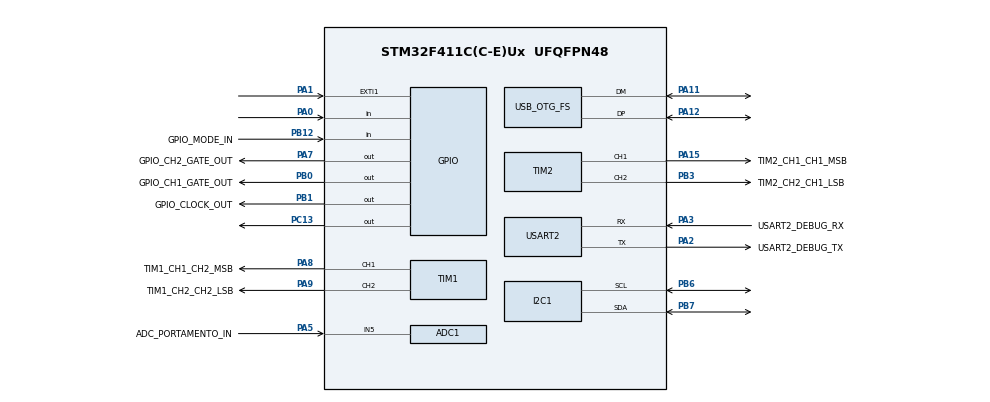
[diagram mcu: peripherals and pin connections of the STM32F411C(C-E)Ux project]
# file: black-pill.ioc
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ADC1.Channel-3\#ChannelRegularConversion=ADC_CHANNEL_5
ADC1.NbrOfConversionFlag=1
ADC1.Rank-3\#ChannelRegularConversion=1
ADC1.SamplingTime-3\#ChannelRegularConversion=ADC_SAMPLETIME_3CYCLES
ADC1.master=1
Mcu.Family=STM32F4
Mcu.Name=STM32F411C(C-E)Ux
Mcu.Package=UFQFPN48
NVIC.PriorityGroup=NVIC_PRIORITYGROUP_4
PA0-WKUP.Signal=GPIO_Input
PA1.Signal=GPXTI1
PA10.GPIO_Label=USART1_MIDI_RX
PA10.GPIO_PuPd=GPIO_PULLUP
PA10.Signal=USART1_RX
PA11.Mode=Device_Only
PA11.Signal=USB_OTG_FS_DM
PA12.Mode=Device_Only
PA12.Signal=USB_OTG_FS_DP
PA13.Mode=Serial_Wire
PA13.Signal=SYS_JTMS-SWDIO
PA14.Mode=Serial_Wire
PA14.Signal=SYS_JTCK-SWCLK
PA15.GPIO_Label=TIM2_CH1_CH1_MSB
PA15.Signal=S_TIM2_CH1_ETR
PA2.GPIO_Label=USART2_DEBUG_TX
PA2.GPIO_PuPd=GPIO_PULLUP
PA2.Mode=Asynchronous
PA2.Signal=USART2_TX
PA3.GPIO_Label=USART2_DEBUG_RX
PA3.GPIO_PuPd=GPIO_PULLUP
PA3.Mode=Asynchronous
PA3.Signal=USART2_RX
PA5.GPIO_Label=ADC_PORTAMENTO_IN
PA5.Signal=ADCx_IN5
PA7.GPIO_Label=GPIO_CH2_GATE_OUT
PA7.Signal=GPIO_Output
PA8.GPIO_Label=TIM1_CH1_CH2_MSB
PA8.GPIO_Speed=GPIO_SPEED_FREQ_VERY_HIGH
PA8.Signal=S_TIM1_CH1
PA9.GPIO_Label=TIM1_CH2_CH2_LSB
PA9.GPIO_Speed=GPIO_SPEED_FREQ_VERY_HIGH
PA9.Signal=S_TIM1_CH2
PB0.GPIO_Label=GPIO_CH1_GATE_OUT
PB0.Signal=GPIO_Output
PB1.GPIO_Label=GPIO_CLOCK_OUT
PB1.Signal=GPIO_Output
PB12.GPIO_Label=GPIO_MODE_IN
PB12.Signal=GPIO_Input
PB3.GPIO_Label=TIM2_CH2_CH1_LSB
PB3.Signal=S_TIM2_CH2
PB6.Mode=I2C
PB6.Signal=I2C1_SCL
PB7.Mode=I2C
PB7.Signal=I2C1_SDA
PC13-ANTI_TAMP.Signal=GPIO_Output
PH0\ -\ OSC_IN.Mode=HSE-External-Oscillator
PH0\ -\ OSC_IN.Signal=RCC_OSC_IN
PH1\ -\ OSC_OUT.Mode=HSE-External-Oscillator
PH1\ -\ OSC_OUT.Signal=RCC_OSC_OUT
ProjectManager.HeapSize=0x200
ProjectManager.StackSize=0x400
ProjectManager.TargetToolchain=Makefile
RCC.48MHZClocksFreq_Value=48000000
RCC.AHBFreq_Value=96000000
RCC.APB1CLKDivider=RCC_HCLK_DIV2
RCC.APB1Freq_Value=48000000
RCC.APB1TimFreq_Value=96000000
RCC.APB2Freq_Value=96000000
RCC.APB2TimFreq_Value=96000000
RCC.CortexFreq_Value=96000000
RCC.HCLKFreq_Value=96000000
RCC.HSE_VALUE=25000000
RCC.HSI_VALUE=16000000
RCC.LSE_VALUE=32768
RCC.PLLM=25
RCC.SYSCLKFreq_VALUE=96000000
RCC.SYSCLKSource=RCC_SYSCLKSOURCE_PLLCLK
RCC.VCOOutputFreq_Value=192000000
SH.ADCx_IN5.0=ADC1_IN5,IN5
SH.S_TIM1_CH1.0=TIM1_CH1,PWM Generation1 CH1
SH.S_TIM1_CH2.0=TIM1_CH2,PWM Generation2 CH2
SH.S_TIM2_CH1_ETR.0=TIM2_CH1,PWM Generation1 CH1
SH.S_TIM2_CH2.0=TIM2_CH2,Output Compare2 CH2
TIM1.AutoReloadPreload=TIM_AUTORELOAD_PRELOAD_ENABLE
TIM1.Channel-PWM\ Generation1\ CH1=TIM_CHANNEL_1
TIM1.Channel-PWM\ Generation2\ CH2=TIM_CHANNEL_2
TIM2.AutoReloadPreload=TIM_AUTORELOAD_PRELOAD_ENABLE
TIM2.Channel-Output\ Compare2\ CH2=TIM_CHANNEL_2
TIM2.Channel-PWM\ Generation1\ CH1=TIM_CHANNEL_1
USART2.VirtualMode=VM_ASYNC
USB_OTG_FS.VirtualMode=Device_Only
VP_TIM1_VS_ClockSourceINT.Mode=Internal
VP_TIM2_VS_ClockSourceINT.Mode=Internal
board=custom

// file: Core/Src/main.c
/* USER CODE BEGIN Header */
/**
  ******************************************************************************
  * @file           : main.c
  * @brief          : Main program body
  ******************************************************************************
  * @attention
  *
  * <h2><center>&copy; Copyright (c) 2021 STMicroelectronics.
  * All rights reserved.</center></h2>
  *
  * This software component is licensed by ST under BSD 3-Clause license,
  * the "License"; You may not use this file except in compliance with the
  * License. You may obtain a copy of the License at:
  *                        opensource.org/licenses/BSD-3-Clause
  *
  ******************************************************************************
  */
/* USER CODE END Header */
#include "main.h"

/* USER CODE BEGIN Includes */
#include "app.h"
#include "usb_device.h"
/* USER CODE END Includes */

void SystemClock_Config(void);
static void MX_GPIO_Init(void);
static void MX_USART2_UART_Init(void);
static void MX_ADC1_Init(void);
static void MX_TIM1_Init(void);
static void MX_TIM2_Init(void);
static void MX_I2C1_Init(void);

int main(void)
{
  /* USER CODE BEGIN 1 */

    /*HAL_Init();
  SystemClock_Config();
  LL_AHB1_GRP1_EnableClock(LL_AHB1_GRP1_PERIPH_GPIOA);
  LL_AHB1_GRP1_EnableClock(LL_AHB1_GRP1_PERIPH_GPIOB);
  LL_AHB1_GRP1_EnableClock(LL_AHB1_GRP1_PERIPH_GPIOC);
  LL_AHB1_GRP1_EnableClock(LL_AHB1_GRP1_PERIPH_GPIOH);
  LL_APB2_GRP1_EnableClock(LL_APB2_GRP1_PERIPH_USART1);
  LL_APB1_GRP1_EnableClock(LL_APB1_GRP1_PERIPH_USART2);
  app_main();
  return 0;*/

  /* USER CODE END 1 */

  /* MCU Configuration--------------------------------------------------------*/

  /* Reset of all peripherals, Initializes the Flash interface and the Systick. */
  HAL_Init();

  /* Configure the system clock */
  SystemClock_Config();

  /* Initialize all configured peripherals */
  MX_GPIO_Init();
  MX_USART2_UART_Init();
  MX_ADC1_Init();
  MX_TIM1_Init();
  MX_TIM2_Init();
  MX_I2C1_Init();
  /* USER CODE BEGIN 2 */
    MX_USB_DEVICE_Init();
    app_main();
  /* USER CODE END 2 */

  /* Infinite loop */
    while(1) {

    }
}

void SystemClock_Config(void)
{
  LL_FLASH_SetLatency(LL_FLASH_LATENCY_3);
  while(LL_FLASH_GetLatency()!= LL_FLASH_LATENCY_3)
  {
  }
  LL_PWR_SetRegulVoltageScaling(LL_PWR_REGU_VOLTAGE_SCALE1);
  LL_RCC_HSE_Enable();

   /* Wait till HSE is ready */
  while(LL_RCC_HSE_IsReady() != 1)
  {

  }
  LL_RCC_PLL_ConfigDomain_SYS(LL_RCC_PLLSOURCE_HSE, LL_RCC_PLLM_DIV_25, 192, LL_RCC_PLLP_DIV_2);
  LL_RCC_PLL_ConfigDomain_48M(LL_RCC_PLLSOURCE_HSE, LL_RCC_PLLM_DIV_25, 192, LL_RCC_PLLQ_DIV_4);
  LL_RCC_PLL_Enable();

   /* Wait till PLL is ready */
  while(LL_RCC_PLL_IsReady() != 1)
  {

  }
  while (LL_PWR_IsActiveFlag_VOS() == 0)
  {
  }
  LL_RCC_SetAHBPrescaler(LL_RCC_SYSCLK_DIV_1);
  LL_RCC_SetAPB1Prescaler(LL_RCC_APB1_DIV_2);
  LL_RCC_SetAPB2Prescaler(LL_RCC_APB2_DIV_1);
  LL_RCC_SetSysClkSource(LL_RCC_SYS_CLKSOURCE_PLL);

   /* Wait till System clock is ready */
  while(LL_RCC_GetSysClkSource() != LL_RCC_SYS_CLKSOURCE_STATUS_PLL)
  {

  }
  LL_SetSystemCoreClock(96000000);

   /* Update the time base */
  if (HAL_InitTick (TICK_INT_PRIORITY) != HAL_OK)
  {
    Error_Handler();
  }
  LL_RCC_SetTIMPrescaler(LL_RCC_TIM_PRESCALER_TWICE);
}

static void MX_ADC1_Init(void)
{

  LL_ADC_InitTypeDef ADC_InitStruct = {0};
  LL_ADC_REG_InitTypeDef ADC_REG_InitStruct = {0};
  LL_ADC_CommonInitTypeDef ADC_CommonInitStruct = {0};

  LL_GPIO_InitTypeDef GPIO_InitStruct = {0};

  /* Peripheral clock enable */
  LL_APB2_GRP1_EnableClock(LL_APB2_GRP1_PERIPH_ADC1);

  LL_AHB1_GRP1_EnableClock(LL_AHB1_GRP1_PERIPH_GPIOA);
  /**ADC1 GPIO Configuration
  PA5   ------> ADC1_IN5
  */
  GPIO_InitStruct.Pin = ADC_PORTAMENTO_IN_Pin;
  GPIO_InitStruct.Mode = LL_GPIO_MODE_ANALOG;
  GPIO_InitStruct.Pull = LL_GPIO_PULL_NO;
  LL_GPIO_Init(ADC_PORTAMENTO_IN_GPIO_Port, &GPIO_InitStruct);

  /** Common config
  */
  ADC_InitStruct.Resolution = LL_ADC_RESOLUTION_12B;
  ADC_InitStruct.DataAlignment = LL_ADC_DATA_ALIGN_RIGHT;
  ADC_InitStruct.SequencersScanMode = LL_ADC_SEQ_SCAN_DISABLE;
  LL_ADC_Init(ADC1, &ADC_InitStruct);
  ADC_REG_InitStruct.TriggerSource = LL_ADC_REG_TRIG_SOFTWARE;
  ADC_REG_InitStruct.SequencerLength = LL_ADC_REG_SEQ_SCAN_DISABLE;
  ADC_REG_InitStruct.SequencerDiscont = LL_ADC_REG_SEQ_DISCONT_DISABLE;
  ADC_REG_InitStruct.ContinuousMode = LL_ADC_REG_CONV_SINGLE;
  ADC_REG_InitStruct.DMATransfer = LL_ADC_REG_DMA_TRANSFER_NONE;
  LL_ADC_REG_Init(ADC1, &ADC_REG_InitStruct);
  LL_ADC_REG_SetFlagEndOfConversion(ADC1, LL_ADC_REG_FLAG_EOC_UNITARY_CONV);
  ADC_CommonInitStruct.CommonClock = LL_ADC_CLOCK_SYNC_PCLK_DIV4;
  LL_ADC_CommonInit(__LL_ADC_COMMON_INSTANCE(ADC1), &ADC_CommonInitStruct);

  /** Configure Regular Channel
  */
  LL_ADC_REG_SetSequencerRanks(ADC1, LL_ADC_REG_RANK_1, LL_ADC_CHANNEL_5);
  LL_ADC_SetChannelSamplingTime(ADC1, LL_ADC_CHANNEL_5, LL_ADC_SAMPLINGTIME_3CYCLES);

}

static void MX_I2C1_Init(void)
{

  LL_I2C_InitTypeDef I2C_InitStruct = {0};

  LL_GPIO_InitTypeDef GPIO_InitStruct = {0};

  LL_AHB1_GRP1_EnableClock(LL_AHB1_GRP1_PERIPH_GPIOB);
  /**I2C1 GPIO Configuration
  PB6   ------> I2C1_SCL
  PB7   ------> I2C1_SDA
  */
  GPIO_InitStruct.Pin = LL_GPIO_PIN_6|LL_GPIO_PIN_7;
  GPIO_InitStruct.Mode = LL_GPIO_MODE_ALTERNATE;
  GPIO_InitStruct.Speed = LL_GPIO_SPEED_FREQ_VERY_HIGH;
  GPIO_InitStruct.OutputType = LL_GPIO_OUTPUT_OPENDRAIN;
  GPIO_InitStruct.Pull = LL_GPIO_PULL_NO;
  GPIO_InitStruct.Alternate = LL_GPIO_AF_4;
  LL_GPIO_Init(GPIOB, &GPIO_InitStruct);

  /* Peripheral clock enable */
  LL_APB1_GRP1_EnableClock(LL_APB1_GRP1_PERIPH_I2C1);

  /** I2C Initialization
  */
  LL_I2C_DisableOwnAddress2(I2C1);
  LL_I2C_DisableGeneralCall(I2C1);
  LL_I2C_EnableClockStretching(I2C1);
  I2C_InitStruct.PeripheralMode = LL_I2C_MODE_I2C;
  I2C_InitStruct.ClockSpeed = 100000;
  I2C_InitStruct.DutyCycle = LL_I2C_DUTYCYCLE_2;
  I2C_InitStruct.OwnAddress1 = 0;
  I2C_InitStruct.TypeAcknowledge = LL_I2C_ACK;
  I2C_InitStruct.OwnAddrSize = LL_I2C_OWNADDRESS1_7BIT;
  LL_I2C_Init(I2C1, &I2C_InitStruct);
  LL_I2C_SetOwnAddress2(I2C1, 0);

}

static void MX_TIM1_Init(void)
{

  LL_TIM_InitTypeDef TIM_InitStruct = {0};
  LL_TIM_OC_InitTypeDef TIM_OC_InitStruct = {0};
  LL_TIM_BDTR_InitTypeDef TIM_BDTRInitStruct = {0};

  LL_GPIO_InitTypeDef GPIO_InitStruct = {0};

  /* Peripheral clock enable */
  LL_APB2_GRP1_EnableClock(LL_APB2_GRP1_PERIPH_TIM1);

  TIM_InitStruct.Prescaler = 0;
  TIM_InitStruct.CounterMode = LL_TIM_COUNTERMODE_UP;
  TIM_InitStruct.Autoreload = 65535;
  TIM_InitStruct.ClockDivision = LL_TIM_CLOCKDIVISION_DIV1;
  TIM_InitStruct.RepetitionCounter = 0;
  LL_TIM_Init(TIM1, &TIM_InitStruct);
  LL_TIM_EnableARRPreload(TIM1);
  LL_TIM_SetClockSource(TIM1, LL_TIM_CLOCKSOURCE_INTERNAL);
  LL_TIM_OC_EnablePreload(TIM1, LL_TIM_CHANNEL_CH1);
  TIM_OC_InitStruct.OCMode = LL_TIM_OCMODE_PWM1;
  TIM_OC_InitStruct.OCState = LL_TIM_OCSTATE_DISABLE;
  TIM_OC_InitStruct.OCNState = LL_TIM_OCSTATE_DISABLE;
  TIM_OC_InitStruct.CompareValue = 0;
  TIM_OC_InitStruct.OCPolarity = LL_TIM_OCPOLARITY_HIGH;
  TIM_OC_InitStruct.OCNPolarity = LL_TIM_OCPOLARITY_HIGH;
  TIM_OC_InitStruct.OCIdleState = LL_TIM_OCIDLESTATE_LOW;
  TIM_OC_InitStruct.OCNIdleState = LL_TIM_OCIDLESTATE_LOW;
  LL_TIM_OC_Init(TIM1, LL_TIM_CHANNEL_CH1, &TIM_OC_InitStruct);
  LL_TIM_OC_DisableFast(TIM1, LL_TIM_CHANNEL_CH1);
  LL_TIM_OC_EnablePreload(TIM1, LL_TIM_CHANNEL_CH2);
  LL_TIM_OC_Init(TIM1, LL_TIM_CHANNEL_CH2, &TIM_OC_InitStruct);
  LL_TIM_OC_DisableFast(TIM1, LL_TIM_CHANNEL_CH2);
  LL_TIM_SetTriggerOutput(TIM1, LL_TIM_TRGO_RESET);
  LL_TIM_DisableMasterSlaveMode(TIM1);
  TIM_BDTRInitStruct.OSSRState = LL_TIM_OSSR_DISABLE;
  TIM_BDTRInitStruct.OSSIState = LL_TIM_OSSI_DISABLE;
  TIM_BDTRInitStruct.LockLevel = LL_TIM_LOCKLEVEL_OFF;
  TIM_BDTRInitStruct.DeadTime = 0;
  TIM_BDTRInitStruct.BreakState = LL_TIM_BREAK_DISABLE;
  TIM_BDTRInitStruct.BreakPolarity = LL_TIM_BREAK_POLARITY_HIGH;
  TIM_BDTRInitStruct.AutomaticOutput = LL_TIM_AUTOMATICOUTPUT_DISABLE;
  LL_TIM_BDTR_Init(TIM1, &TIM_BDTRInitStruct);
  LL_AHB1_GRP1_EnableClock(LL_AHB1_GRP1_PERIPH_GPIOA);
  /**TIM1 GPIO Configuration
  PA8   ------> TIM1_CH1
  PA9   ------> TIM1_CH2
  */
  GPIO_InitStruct.Pin = TIM1_CH1_CH2_MSB_Pin|TIM1_CH2_CH2_LSB_Pin;
  GPIO_InitStruct.Mode = LL_GPIO_MODE_ALTERNATE;
  GPIO_InitStruct.Speed = LL_GPIO_SPEED_FREQ_VERY_HIGH;
  GPIO_InitStruct.OutputType = LL_GPIO_OUTPUT_PUSHPULL;
  GPIO_InitStruct.Pull = LL_GPIO_PULL_NO;
  GPIO_InitStruct.Alternate = LL_GPIO_AF_1;
  LL_GPIO_Init(GPIOA, &GPIO_InitStruct);

}

static void MX_TIM2_Init(void)
{

  LL_TIM_InitTypeDef TIM_InitStruct = {0};
  LL_TIM_OC_InitTypeDef TIM_OC_InitStruct = {0};

  LL_GPIO_InitTypeDef GPIO_InitStruct = {0};

  /* Peripheral clock enable */
  LL_APB1_GRP1_EnableClock(LL_APB1_GRP1_PERIPH_TIM2);

  TIM_InitStruct.Prescaler = 0;
  TIM_InitStruct.CounterMode = LL_TIM_COUNTERMODE_UP;
  TIM_InitStruct.Autoreload = 4294967295;
  TIM_InitStruct.ClockDivision = LL_TIM_CLOCKDIVISION_DIV1;
  LL_TIM_Init(TIM2, &TIM_InitStruct);
  LL_TIM_EnableARRPreload(TIM2);
  LL_TIM_SetClockSource(TIM2, LL_TIM_CLOCKSOURCE_INTERNAL);
  LL_TIM_OC_EnablePreload(TIM2, LL_TIM_CHANNEL_CH1);
  TIM_OC_InitStruct.OCMode = LL_TIM_OCMODE_PWM1;
  TIM_OC_InitStruct.OCState = LL_TIM_OCSTATE_DISABLE;
  TIM_OC_InitStruct.OCNState = LL_TIM_OCSTATE_DISABLE;
  TIM_OC_InitStruct.CompareValue = 0;
  TIM_OC_InitStruct.OCPolarity = LL_TIM_OCPOLARITY_HIGH;
  LL_TIM_OC_Init(TIM2, LL_TIM_CHANNEL_CH1, &TIM_OC_InitStruct);
  LL_TIM_OC_DisableFast(TIM2, LL_TIM_CHANNEL_CH1);
  TIM_OC_InitStruct.OCMode = LL_TIM_OCMODE_FROZEN;
  LL_TIM_OC_Init(TIM2, LL_TIM_CHANNEL_CH2, &TIM_OC_InitStruct);
  LL_TIM_OC_DisableFast(TIM2, LL_TIM_CHANNEL_CH2);
  LL_TIM_SetTriggerOutput(TIM2, LL_TIM_TRGO_RESET);
  LL_TIM_DisableMasterSlaveMode(TIM2);
  LL_AHB1_GRP1_EnableClock(LL_AHB1_GRP1_PERIPH_GPIOA);
  LL_AHB1_GRP1_EnableClock(LL_AHB1_GRP1_PERIPH_GPIOB);
  /**TIM2 GPIO Configuration
  PA15   ------> TIM2_CH1
  PB3   ------> TIM2_CH2
  */
  GPIO_InitStruct.Pin = TIM2_CH1_CH1_MSB_Pin;
  GPIO_InitStruct.Mode = LL_GPIO_MODE_ALTERNATE;
  GPIO_InitStruct.Speed = LL_GPIO_SPEED_FREQ_LOW;
  GPIO_InitStruct.OutputType = LL_GPIO_OUTPUT_PUSHPULL;
  GPIO_InitStruct.Pull = LL_GPIO_PULL_NO;
  GPIO_InitStruct.Alternate = LL_GPIO_AF_1;
  LL_GPIO_Init(TIM2_CH1_CH1_MSB_GPIO_Port, &GPIO_InitStruct);

  GPIO_InitStruct.Pin = TIM2_CH2_CH1_LSB_Pin;
  GPIO_InitStruct.Mode = LL_GPIO_MODE_ALTERNATE;
  GPIO_InitStruct.Speed = LL_GPIO_SPEED_FREQ_LOW;
  GPIO_InitStruct.OutputType = LL_GPIO_OUTPUT_PUSHPULL;
  GPIO_InitStruct.Pull = LL_GPIO_PULL_NO;
  GPIO_InitStruct.Alternate = LL_GPIO_AF_1;
  LL_GPIO_Init(TIM2_CH2_CH1_LSB_GPIO_Port, &GPIO_InitStruct);

}

static void MX_USART2_UART_Init(void)
{

  LL_USART_InitTypeDef USART_InitStruct = {0};

  LL_GPIO_InitTypeDef GPIO_InitStruct = {0};

  /* Peripheral clock enable */
  LL_APB1_GRP1_EnableClock(LL_APB1_GRP1_PERIPH_USART2);

  LL_AHB1_GRP1_EnableClock(LL_AHB1_GRP1_PERIPH_GPIOA);
  /**USART2 GPIO Configuration
  PA2   ------> USART2_TX
  PA3   ------> USART2_RX
  */
  GPIO_InitStruct.Pin = USART2_DEBUG_TX_Pin|USART2_DEBUG_RX_Pin;
  GPIO_InitStruct.Mode = LL_GPIO_MODE_ALTERNATE;
  GPIO_InitStruct.Speed = LL_GPIO_SPEED_FREQ_VERY_HIGH;
  GPIO_InitStruct.OutputType = LL_GPIO_OUTPUT_PUSHPULL;
  GPIO_InitStruct.Pull = LL_GPIO_PULL_UP;
  GPIO_InitStruct.Alternate = LL_GPIO_AF_7;
  LL_GPIO_Init(GPIOA, &GPIO_InitStruct);

  /* USER CODE BEGIN USART2_Init 1 */
    return;
  /* USER CODE END USART2_Init 1 */
  USART_InitStruct.BaudRate = 115200;
  USART_InitStruct.DataWidth = LL_USART_DATAWIDTH_8B;
  USART_InitStruct.StopBits = LL_USART_STOPBITS_1;
  USART_InitStruct.Parity = LL_USART_PARITY_NONE;
  USART_InitStruct.TransferDirection = LL_USART_DIRECTION_TX_RX;
  USART_InitStruct.HardwareFlowControl = LL_USART_HWCONTROL_NONE;
  USART_InitStruct.OverSampling = LL_USART_OVERSAMPLING_16;
  LL_USART_Init(USART2, &USART_InitStruct);
  LL_USART_ConfigAsyncMode(USART2);
  LL_USART_Enable(USART2);

}

static void MX_GPIO_Init(void)
{
  LL_EXTI_InitTypeDef EXTI_InitStruct = {0};
  LL_GPIO_InitTypeDef GPIO_InitStruct = {0};

  /* GPIO Ports Clock Enable */
  LL_AHB1_GRP1_EnableClock(LL_AHB1_GRP1_PERIPH_GPIOC);
  LL_AHB1_GRP1_EnableClock(LL_AHB1_GRP1_PERIPH_GPIOH);
  LL_AHB1_GRP1_EnableClock(LL_AHB1_GRP1_PERIPH_GPIOA);
  LL_AHB1_GRP1_EnableClock(LL_AHB1_GRP1_PERIPH_GPIOB);

  /**/
  LL_GPIO_ResetOutputPin(GPIOC, LL_GPIO_PIN_13);

  /**/
  LL_GPIO_ResetOutputPin(GPIO_CH2_GATE_OUT_GPIO_Port, GPIO_CH2_GATE_OUT_Pin);

  /**/
  LL_GPIO_ResetOutputPin(GPIOB, GPIO_CH1_GATE_OUT_Pin|GPIO_CLOCK_OUT_Pin);

  /**/
  GPIO_InitStruct.Pin = LL_GPIO_PIN_13;
  GPIO_InitStruct.Mode = LL_GPIO_MODE_OUTPUT;
  GPIO_InitStruct.Speed = LL_GPIO_SPEED_FREQ_LOW;
  GPIO_InitStruct.OutputType = LL_GPIO_OUTPUT_PUSHPULL;
  GPIO_InitStruct.Pull = LL_GPIO_PULL_NO;
  LL_GPIO_Init(GPIOC, &GPIO_InitStruct);

  /**/
  GPIO_InitStruct.Pin = LL_GPIO_PIN_0;
  GPIO_InitStruct.Mode = LL_GPIO_MODE_INPUT;
  GPIO_InitStruct.Pull = LL_GPIO_PULL_NO;
  LL_GPIO_Init(GPIOA, &GPIO_InitStruct);

  /**/
  GPIO_InitStruct.Pin = GPIO_CH2_GATE_OUT_Pin;
  GPIO_InitStruct.Mode = LL_GPIO_MODE_OUTPUT;
  GPIO_InitStruct.Speed = LL_GPIO_SPEED_FREQ_LOW;
  GPIO_InitStruct.OutputType = LL_GPIO_OUTPUT_PUSHPULL;
  GPIO_InitStruct.Pull = LL_GPIO_PULL_NO;
  LL_GPIO_Init(GPIO_CH2_GATE_OUT_GPIO_Port, &GPIO_InitStruct);

  /**/
  GPIO_InitStruct.Pin = GPIO_CH1_GATE_OUT_Pin|GPIO_CLOCK_OUT_Pin;
  GPIO_InitStruct.Mode = LL_GPIO_MODE_OUTPUT;
  GPIO_InitStruct.Speed = LL_GPIO_SPEED_FREQ_LOW;
  GPIO_InitStruct.OutputType = LL_GPIO_OUTPUT_PUSHPULL;
  GPIO_InitStruct.Pull = LL_GPIO_PULL_NO;
  LL_GPIO_Init(GPIOB, &GPIO_InitStruct);

  /**/
  GPIO_InitStruct.Pin = GPIO_MODE_IN_Pin;
  GPIO_InitStruct.Mode = LL_GPIO_MODE_INPUT;
  GPIO_InitStruct.Pull = LL_GPIO_PULL_NO;
  LL_GPIO_Init(GPIO_MODE_IN_GPIO_Port, &GPIO_InitStruct);

  /**/
  GPIO_InitStruct.Pin = USART1_MIDI_RX_Pin;
  GPIO_InitStruct.Mode = LL_GPIO_MODE_ALTERNATE;
  GPIO_InitStruct.Speed = LL_GPIO_SPEED_FREQ_VERY_HIGH;
  GPIO_InitStruct.OutputType = LL_GPIO_OUTPUT_PUSHPULL;
  GPIO_InitStruct.Pull = LL_GPIO_PULL_UP;
  GPIO_InitStruct.Alternate = LL_GPIO_AF_7;
  LL_GPIO_Init(USART1_MIDI_RX_GPIO_Port, &GPIO_InitStruct);

  /**/
  LL_SYSCFG_SetEXTISource(LL_SYSCFG_EXTI_PORTA, LL_SYSCFG_EXTI_LINE1);

  /**/
  EXTI_InitStruct.Line_0_31 = LL_EXTI_LINE_1;
  EXTI_InitStruct.LineCommand = ENABLE;
  EXTI_InitStruct.Mode = LL_EXTI_MODE_IT;
  EXTI_InitStruct.Trigger = LL_EXTI_TRIGGER_RISING;
  LL_EXTI_Init(&EXTI_InitStruct);

  /**/
  LL_GPIO_SetPinPull(GPIOA, LL_GPIO_PIN_1, LL_GPIO_PULL_NO);

  /**/
  LL_GPIO_SetPinMode(GPIOA, LL_GPIO_PIN_1, LL_GPIO_MODE_INPUT);

}

void Error_Handler(void)
{
  /* USER CODE BEGIN Error_Handler_Debug */
    /* User can add his own implementation to report the HAL error return state */
    __disable_irq();
    asm("bkpt 1");
    while(1) {
    }
  /* USER CODE END Error_Handler_Debug */
}
